# ATBTLC1000WLCSP register map
Vendor: Atmel Corp; Series: SAMB11; File version: TODO
CPU: CM0 r0p0, little endian, no MPU, no FPU, 2 interrupt priority bits
Address unit: 32 bits
Registers are 32-bit, read-write, reset 0x0 unless marked. A register's access mark holds for its fields unless they carry their own. Offsets are from the block's base; [hi:lo] are bit positions; {n}, {i} and the like mark numbered series; 'fields as' and 'values as' point back to an identical list.

## PROV_DMA_CTRL0 — 4 Channel DMA Controller
Base 0x40002000
{0x0+0x100*i} CH{i}_CMD_REG0 (i=0..3) — Channel {i} First Line Channel Command
  [31:0] RD_START_ADDR — Start Address of Read Buffer
{0x4+0x100*i} CH{i}_CMD_REG1 (i=0..3) — Channel {i} Second Line Channel Command
  [31:0] WR_START_ADDR — Start Address of Write Buffer
{0x8+0x100*i} CH{i}_CMD_REG2 16-bit (i=0..3) — Channel {i} Third Line Channel Command
  [12:0] BUFFER_SIZE — Size (in Bytes) of Buffer to Transfer
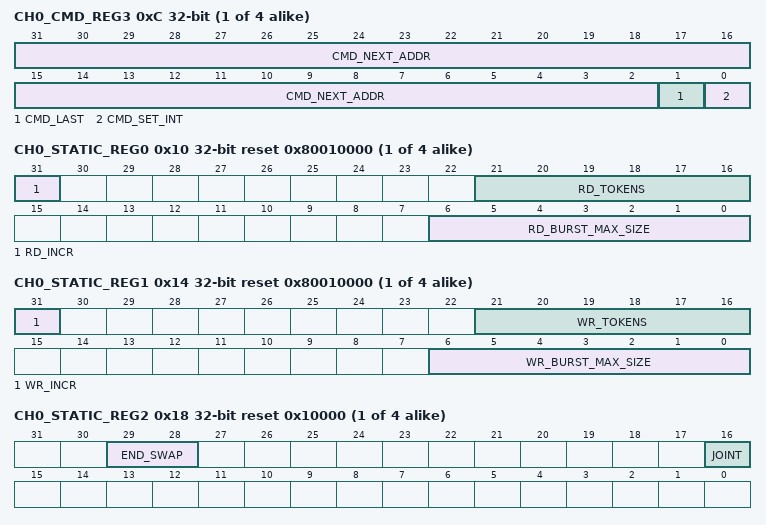
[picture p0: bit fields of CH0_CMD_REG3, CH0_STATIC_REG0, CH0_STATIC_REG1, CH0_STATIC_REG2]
{0xC+0x100*i} CH{i}_CMD_REG3 (i=0..3) — Channel {i} Fourth Line Channel Command
  [31:2] CMD_NEXT_ADDR — Address of next command if CMD_LAST is not set
  [1] CMD_LAST — If set, channel stops when buffer done, otherwise load from CMD_NEXT_ADDR
  [0] CMD_SET_INT — Active High Interrupt Enable once buffer has been transfered
{0x10+0x100*i} CH{i}_STATIC_REG0 reset 0x80010000 (i=0..3) — Channel {i} Static Configuration Read
  [31] RD_INCR — If set the controller will increment the next burst address
  [21:16] RD_TOKENS — Number of AHB read commands to issue before channel is released
  [6:0] RD_BURST_MAX_SIZE — Maximum number of bytes of an AHB read burst
{0x14+0x100*i} CH{i}_STATIC_REG1 reset 0x80010000 (i=0..3) — Channel {i} Static Configuration Write
  [31] WR_INCR — If set the controller will increment the next burst address
  [21:16] WR_TOKENS — Number of AHB write commands to issue before channel is released
  [6:0] WR_BURST_MAX_SIZE — Maximum number of bytes of an AHB write burst
{0x18+0x100*i} CH{i}_STATIC_REG2 reset 0x10000 (i=0..3) — Channel {i} Block Mode
  [29:28] END_SWAP — Endianness Byte Swapping
    0=No Swapping; 1=Swap bytes within 16 bits; 2=Swap bytes within 32 bits; 3=Swap bytes within 64 bits
  [16] JOINT — If set channel will work in joint mode
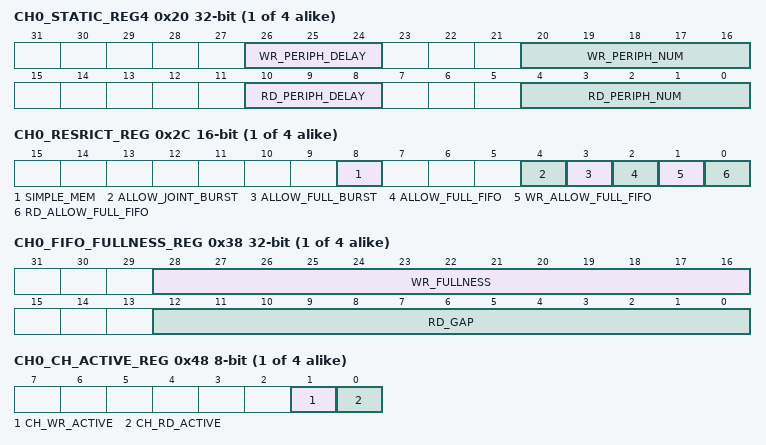
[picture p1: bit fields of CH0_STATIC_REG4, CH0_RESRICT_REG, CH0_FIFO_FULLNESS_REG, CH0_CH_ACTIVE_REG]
{0x20+0x100*i} CH{i}_STATIC_REG4 (i=0..3) — Channel {i} Static Configuration Peripheral
  [26:24] WR_PERIPH_DELAY — Number of cycles to wait for write request signal to update after issuing the write clear signal
  [20:16] WR_PERIPH_NUM — Number of peripheral to write from (0 if memory or no peripheral flow control)
  [10:8] RD_PERIPH_DELAY — Number of cycles to wait for read request signal to update after issuing the read clear signal
  [4:0] RD_PERIPH_NUM — Number of peripheral to read from (0 if memory or no peripheral flow control)
{0x2C+0x100*i} CH{i}_RESRICT_REG 16-bit ro (i=0..3) — Channel {i} Restrictions Status Register
  [8] SIMPLE_MEM — Configuration is aligned and peripherals are not used
  [4] ALLOW_JOINT_BURST — Joint bursts are currently active
  [3] ALLOW_FULL_BURST — Maximum burst of 16 strobes can be used (joint mode only)
  [2] ALLOW_FULL_FIFO — Burst sizes can equal data buffer size, otherwise max burst is half data buffer size
  [1] WR_ALLOW_FULL_FIFO — Write start address does not restrict burst size
  [0] RD_ALLOW_FULL_FIFO — Read start address does not restrict burst size
{0x38+0x100*i} CH{i}_FIFO_FULLNESS_REG ro (i=0..3) — Channel {i} FIFO Fullness Status Register
  [28:16] WR_FULLNESS — Occupied space (in bytes) in FIFO by write data
  [12:0] RD_GAP — Remaining space (in bytes) in FIFO for read data
{0x40+0x100*i} CH{i}_CH_ENABLE_REG 8-bit reset 0x1 (reset mask 0x1) (i=0..3) — Channel {i} Channel Enable Register
{0x44+0x100*i} CH{i}_CH_START_REG 8-bit wo (reset mask 0x1) (i=0..3) — Channel {i} Channel Start Register
{0x48+0x100*i} CH{i}_CH_ACTIVE_REG 8-bit ro (i=0..3) — Channel {i} Channel Active Status Register
  [1] CH_WR_ACTIVE — Set if channel is enabled and all write data has been transfered
  [0] CH_RD_ACTIVE — Set if channel is enabled and all read data has been received
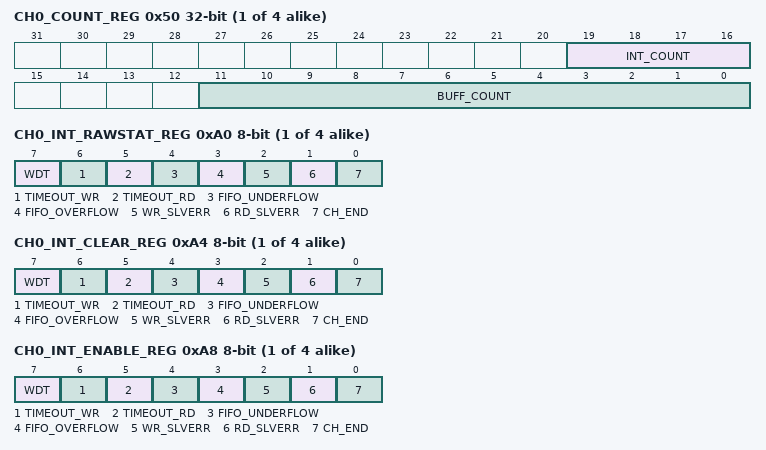
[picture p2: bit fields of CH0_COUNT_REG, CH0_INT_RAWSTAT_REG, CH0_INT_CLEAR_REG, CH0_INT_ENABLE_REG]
{0x50+0x100*i} CH{i}_COUNT_REG ro (i=0..3) — Channel {i} Buffer Counter Status Register
  [19:16] INT_COUNT — Number of unserviced end interrupts
  [11:0] BUFF_COUNT — Number of buffers transferred by channel since started
{0xA0+0x100*i} CH{i}_INT_RAWSTAT_REG 8-bit (i=0..3) — Channel {i} Interrupt Raw Status (Write 1 to any field to issue interrupt)
  [7] WDT — Channel active but did not start a burst for 2048 cycles
  [6] TIMEOUT_WR — Write timeout on AHB bus (timeout value fixed at 1024 cycles)
  [5] TIMEOUT_RD — Read timeout on AHB bus (timeout value fixed at 1024 cycles)
  [4] FIFO_UNDERFLOW — FIFO has been underflown
  [3] FIFO_OVERFLOW — FIFO has been overflown
  [2] WR_SLVERR — AHB write slave error
  [1] RD_SLVERR — AHB read slave error
  [0] CH_END — Indicates an unserviced channel end interrupt
{0xA4+0x100*i} CH{i}_INT_CLEAR_REG 8-bit (i=0..3) — Channel {i} Interrupt Clear (Write 1 to clear)
  [7] WDT — Clears WDT
  [6] TIMEOUT_WR — Clears Write Timeout
  [5] TIMEOUT_RD — Clears Read Timeout
  [4] FIFO_UNDERFLOW — Clears FIFO underflow
  [3] FIFO_OVERFLOW — Clears FIFO overflow
  [2] WR_SLVERR — Clear AHB write slave error
  [1] RD_SLVERR — Clear AHB read slave error
  [0] CH_END — Clear channel end interrupt. Decrements INT_COUNT register
{0xA8+0x100*i} CH{i}_INT_ENABLE_REG 8-bit (i=0..3) — Channel {i} Interrupt Enable
  [7] WDT — Enables WDT interrupt
  [6] TIMEOUT_WR — Enables AHB Write timeout interrupt
  [5] TIMEOUT_RD — Enables AHB Read timeout interrupt
  [4] FIFO_UNDERFLOW — Enables FIFO underflow interrupt
  [3] FIFO_OVERFLOW — Enables FIFO overflow interrupt
  [2] WR_SLVERR — Enables AHB write slave error interrupt
  [1] RD_SLVERR — Enables AHB read slave error interrupt
  [0] CH_END — Enables end of channel interrupt
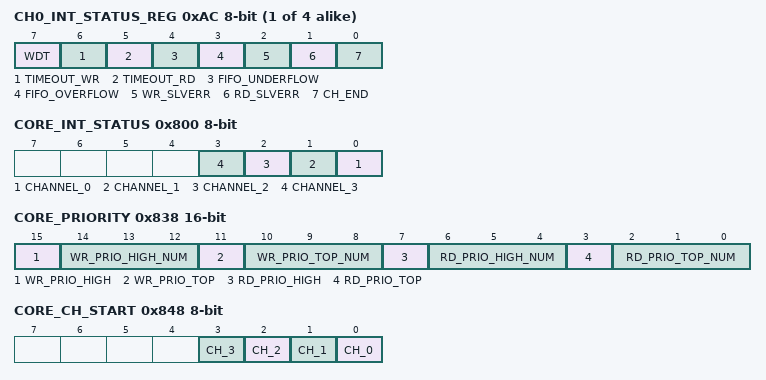
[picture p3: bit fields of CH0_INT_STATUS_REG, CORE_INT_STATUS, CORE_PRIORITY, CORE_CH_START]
{0xAC+0x100*i} CH{i}_INT_STATUS_REG 8-bit (i=0..3) — Channel {i} Interrupt Status
  fields as CH0_INT_RAWSTAT_REG
0x800 CORE_INT_STATUS 8-bit ro — Indicates which channels caused interrupt
  [n] CHANNEL_{n} (n=0..3) — Indicates channel {n} caused interrupt
0x830 CORE_JOINT_MODE 8-bit (reset mask 0x1) — If set, core works in joint mode
0x838 CORE_PRIORITY 16-bit — Core Priority Channels
  [15] WR_PRIO_HIGH — Core Write High Priority Enable
  [14:12] WR_PRIO_HIGH_NUM — Core Write High Priority Channel Number
  [11] WR_PRIO_TOP — Core Write Top Priority Enable
  [10:8] WR_PRIO_TOP_NUM — Core Write Top Priority Channel Number
  [7] RD_PRIO_HIGH — Core Read High Priority Enable
  [6:4] RD_PRIO_HIGH_NUM — Core Read High Priority Channel Number
  [3] RD_PRIO_TOP — Core Read Top Priority Enable
  [2:0] RD_PRIO_TOP_NUM — Core Read Top Priority Channel Number
0x840 CORE_CLKDIV 8-bit reset 0x1 (reset mask 0xF) — Ratio between main clock and core clock
0x848 CORE_CH_START 8-bit wo — Channel Start
  [n] CH_{n} (n=0..3) — Starts Channel {n}
0x850 PERIPH_RX_CTRL — Direct control of peripheral RX request
  [31:1] RX_REQ — Allows direct control of the peripheral RX request bus
0x860 PERIPH_TX_CTRL — Direct control of peripheral TX request
  [31:1] TX_REQ — Allows direct control of the peripheral TX request bus
0x8D0 CORE_IDLE 8-bit ro (reset mask 0x1) — Indicates all channels have stopped and transactions have completed
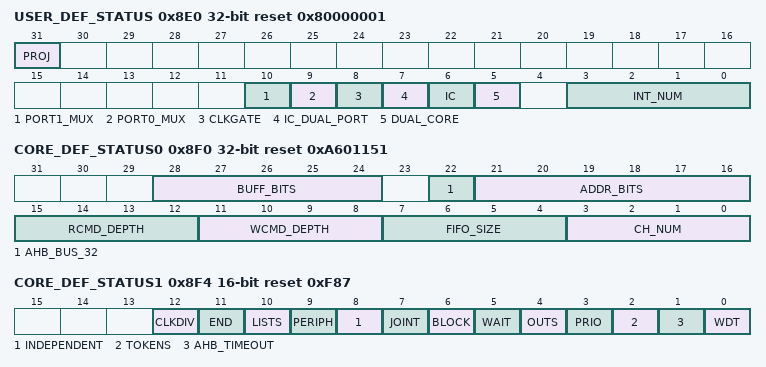
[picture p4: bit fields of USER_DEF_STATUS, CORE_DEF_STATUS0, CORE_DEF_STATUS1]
0x8E0 USER_DEF_STATUS ro reset 0x80000001 — User Defined Configurations
  [31] PROJ — User Defined Project
  [10] PORT1_MUX — If set AHB port 1 is using an AHB mux
  [9] PORT0_MUX — If set AHB port 0 is using an AHB mux
  [8] CLKGATE — If set design contains functional clock gates
  [7] IC_DUAL_PORT — If set AHB matrix has two output ports
  [6] IC — If set an AHB matrix is used
  [5] DUAL_CORE — If set the design has two cores
  [3:0] INT_NUM — Number of bits in interrupt bus
0x8F0 CORE_DEF_STATUS0 ro reset 0xA601151 — User Defined Core Configurations 0
  [28:24] BUFF_BITS — Number of bits in BUFFER_SIZE
  [22] AHB_BUS_32 — If set AHB bus is 32 bit otherwise 64 bit
  [21:16] ADDR_BITS — Number of bits in address buses
  [15:12] RCMD_DEPTH — Log2 of maximum number of pending read commands
  [11:8] WCMD_DEPTH — Log2 of maximum number of pending write commands
  [7:4] FIFO_SIZE — Log2 of FIFO size per channel
  [3:0] CH_NUM — Number of channels (reads 1, should read 4)
0x8F4 CORE_DEF_STATUS1 16-bit ro reset 0xF87 — User Defined Core Configurations 1
  [12] CLKDIV — Set if core supports clock division ratios
  [11] END — Set if core supports endianness swapping
  [10] LISTS — Set if core supports command lists
  [9] PERIPH — Set if core supports peripherals
  [8] INDEPENDENT — Set if core supports independent mode
  [7] JOINT — Set if core supports joint mode
  [6] BLOCK — Set if core supports block transfer
  [5] WAIT — Set if core supports scheduled channels
  [4] OUTS — Set if core supports outstanding mode
  [3] PRIO — Set if core has priority modes support
  [2] TOKENS — Set if core has tokens support
  [1] AHB_TIMEOUT — Set if core supports timeouts on AHB read and write buses
  [0] WDT — Set if core has watchdog timer

## Notices in the file
Copyright (c) 2015, Atmel Corporation
All rights reserved.
Redistribution and use in source and binary forms, with or without
modification, are permitted provided that the following condition is met:
- Redistributions of source code must retain the above copyright notice,
this list of conditions and the disclaimer below.
Atmel's name may not be used to endorse or promote products derived from
this software without specific prior written permission.
DISCLAIMER: THIS SOFTWARE IS PROVIDED BY ATMEL "AS IS" AND ANY EXPRESS OR
IMPLIED WARRANTIES, INCLUDING, BUT NOT LIMITED TO, THE IMPLIED WARRANTIES OF
MERCHANTABILITY, FITNESS FOR A PARTICULAR PURPOSE AND NON-INFRINGEMENT ARE
DISCLAIMED. IN NO EVENT SHALL ATMEL BE LIABLE FOR ANY DIRECT, INDIRECT,
INCIDENTAL, SPECIAL, EXEMPLARY, OR CONSEQUENTIAL DAMAGES (INCLUDING, BUT NOT
LIMITED TO, PROCUREMENT OF SUBSTITUE GOODS OR SERVICES; LOSS OF USE, DATA,
OR PROFITS; OR BUSINESS INTERRUPTION) HOWEVER CAUSE AND ON ANY THEORY OF
LIABILITY, WHETHER IN CONTRACT, STRICT LIABILITY, OR TORT (INCLUDING
NEGLIGENCE OR OTHERWISE) ARISING IN ANY WAY OUT OF THE USE OF THIS SOFTWARE,
EVEN IF ADVISED OF THE POSSIBILITY OF SUCH DAMAGE.
Atmel software license text goes here
TODO
